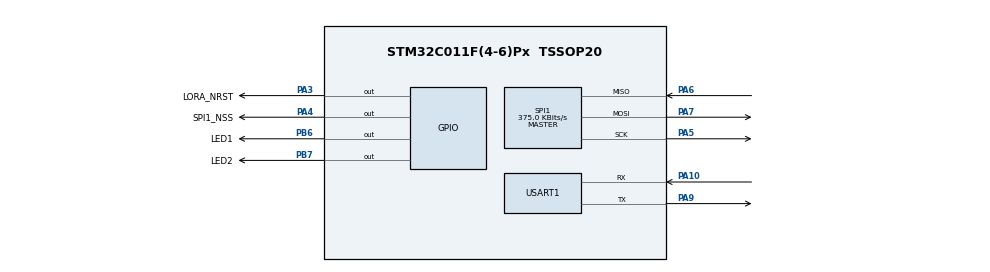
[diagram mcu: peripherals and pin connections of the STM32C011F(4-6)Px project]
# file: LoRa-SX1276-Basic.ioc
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Mcu.Family=STM32C0
Mcu.Name=STM32C011F(4-6)Px
Mcu.Package=TSSOP20
PA10\ [PA12].Mode=Asynchronous
PA10\ [PA12].Signal=USART1_RX
PA13.Mode=Serial_Wire
PA13.Signal=DEBUG_SWDIO
PA14-BOOT0.Mode=Serial_Wire
PA14-BOOT0.Signal=DEBUG_SWCLK
PA3.GPIO_Label=LORA_NRST
PA3.Signal=GPIO_Output
PA4.GPIO_Label=SPI1_NSS
PA4.Signal=GPIO_Output
PA5.Mode=Full_Duplex_Master
PA5.Signal=SPI1_SCK
PA6.Mode=Full_Duplex_Master
PA6.Signal=SPI1_MISO
PA7.Mode=Full_Duplex_Master
PA7.Signal=SPI1_MOSI
PA9\ [PA11].Mode=Asynchronous
PA9\ [PA11].Signal=USART1_TX
PB6.GPIO_Label=LED1
PB6.Signal=GPIO_Output
PB7.GPIO_Label=LED2
PB7.Signal=GPIO_Output
ProjectManager.HeapSize=0x200
ProjectManager.StackSize=0x400
ProjectManager.TargetToolchain=STM32CubeIDE
RCC.ADCFreq_Value=48000000
RCC.AHBFreq_Value=48000000
RCC.CortexFreq_Value=48000000
RCC.EXTERNAL_CLOCK_VALUE=12288000
RCC.HCLKFreq_Value=48000000
RCC.HSE_VALUE=8000000
RCC.HSISYSCLKDivider=RCC_HSI_DIV1
RCC.HSI_VALUE=48000000
RCC.LSE_VALUE=32768
RCC.SYSCLKFreq_VALUE=48000000
SPI1.BaudRatePrescaler=SPI_BAUDRATEPRESCALER_128
SPI1.CalculateBaudRate=375.0 KBits/s
SPI1.Direction=SPI_DIRECTION_2LINES
SPI1.Mode=SPI_MODE_MASTER
SPI1.VirtualType=VM_MASTER
USART1.VirtualMode-Asynchronous=VM_ASYNC
VP_SYS_VS_PINREMAP.Mode=PINREMAP
VP_SYS_VS_PINREMAP_10_12.Mode=PINREMAP_10_12
board=custom

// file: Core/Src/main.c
/* USER CODE BEGIN Header */
/**
  ******************************************************************************
  * @file           : main.c
  * @brief          : Main program body
  ******************************************************************************
  * @attention
  *
  * Copyright (c) 2024 STMicroelectronics.
  * All rights reserved.
  *
  * This software is licensed under terms that can be found in the LICENSE file
  * in the root directory of this software component.
  * If no LICENSE file comes with this software, it is provided AS-IS.
  *
  ******************************************************************************
  */
/* USER CODE END Header */
#include "main.h"
#include "spi.h"
#include "usart.h"
#include "gpio.h"

/* USER CODE BEGIN Includes */

#include "app.h"

/* USER CODE END Includes */

void SystemClock_Config(void);

int main(void)
{

  /* MCU Configuration--------------------------------------------------------*/

  /* Reset of all peripherals, Initializes the Flash interface and the Systick. */
  HAL_Init();

  /* Configure the system clock */
  SystemClock_Config();

  /* Initialize all configured peripherals */
  MX_GPIO_Init();
  MX_SPI1_Init();
  MX_USART1_UART_Init();
  /* USER CODE BEGIN 2 */

  APP_Init();	// Program enters this function and should never return; infinite loop on APP_Run();

  /* USER CODE END 2 */

  /* Infinite loop */
  while (1)
  {

  }
}

void SystemClock_Config(void)
{
  RCC_OscInitTypeDef RCC_OscInitStruct = {0};
  RCC_ClkInitTypeDef RCC_ClkInitStruct = {0};

  /** Initializes the RCC Oscillators according to the specified parameters
  * in the RCC_OscInitTypeDef structure.
  */
  RCC_OscInitStruct.OscillatorType = RCC_OSCILLATORTYPE_HSI;
  RCC_OscInitStruct.HSIState = RCC_HSI_ON;
  RCC_OscInitStruct.HSIDiv = RCC_HSI_DIV1;
  RCC_OscInitStruct.HSICalibrationValue = RCC_HSICALIBRATION_DEFAULT;
  if (HAL_RCC_OscConfig(&RCC_OscInitStruct) != HAL_OK)
  {
    Error_Handler();
  }

  /** Initializes the CPU, AHB and APB buses clocks
  */
  RCC_ClkInitStruct.ClockType = RCC_CLOCKTYPE_HCLK|RCC_CLOCKTYPE_SYSCLK
                              |RCC_CLOCKTYPE_PCLK1;
  RCC_ClkInitStruct.SYSCLKSource = RCC_SYSCLKSOURCE_HSI;
  RCC_ClkInitStruct.SYSCLKDivider = RCC_SYSCLK_DIV1;
  RCC_ClkInitStruct.AHBCLKDivider = RCC_HCLK_DIV1;
  RCC_ClkInitStruct.APB1CLKDivider = RCC_APB1_DIV1;

  if (HAL_RCC_ClockConfig(&RCC_ClkInitStruct, FLASH_LATENCY_1) != HAL_OK)
  {
    Error_Handler();
  }
}

void Error_Handler(void)
{
  __disable_irq();
  while (1)
  {
  }
}
